VERSION ""

NS_ :

BS_:

BU_:

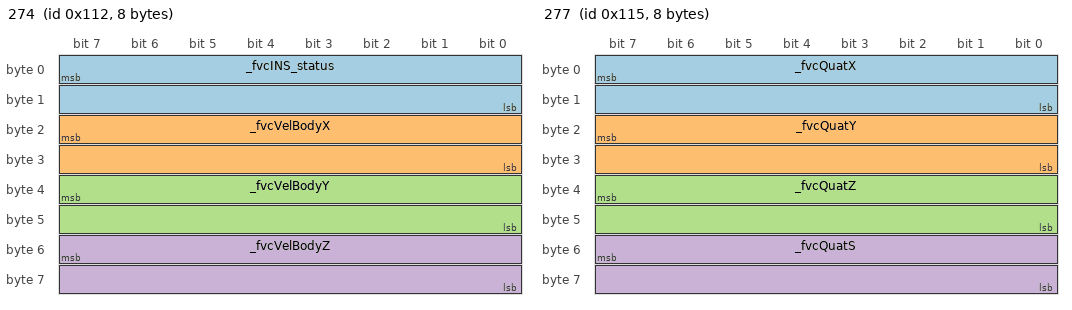
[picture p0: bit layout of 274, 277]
BO_ 274 274: 8 Vector__XXX
 SG_ _fvcINS_status : 7|16@0+ (1,0) [0|0] "unitless:" Vector__XXX
 SG_ _fvcVelBodyX : 23|16@0- (0.00427246,-70) [0|0] "unitless:" Vector__XXX
 SG_ _fvcVelBodyY : 39|16@0- (0.00427246,-70) [0|0] "unitless:" Vector__XXX
 SG_ _fvcVelBodyZ : 55|16@0- (0.00427246,-70) [0|0] "unitless:" Vector__XXX

BO_ 275 275: 8 Vector__XXX
 SG_ _fvcLatitude : 7|32@0- (0.00549324788,-90) [0|0] "angle:deg" Vector__XXX
 SG_ _fvcLongitude : 39|32@0- (0.01098633,-180) [0|0] "angle:deg" Vector__XXX

BO_ 276 276: 8 Vector__XXX
 SG_ _fvcYaw : 7|32@0- (1.67638063e-07,-180) [0|0] "angle:deg" Vector__XXX
 SG_ _fvcPitch : 39|16@0- (0.00549316406,-90) [0|0] "angle:deg" Vector__XXX
 SG_ _fvcRoll : 55|16@0- (0.01098632812,-180) [0|0] "angle:deg" Vector__XXX

BO_ 277 277: 8 Vector__XXX
 SG_ _fvcQuatX : 7|16@0- (6.103515e-05,-1) [0|0] "unitless:" Vector__XXX
 SG_ _fvcQuatY : 23|16@0- (6.103515e-05,-1) [0|0] "unitless:" Vector__XXX
 SG_ _fvcQuatZ : 39|16@0- (6.103515e-05,-1) [0|0] "unitless:" Vector__XXX
 SG_ _fvcQuatS : 55|16@0- (6.103515e-05,-1) [0|0] "unitless:" Vector__XXX

BO_ 278 278: 8 Vector__XXX
 SG_ _fvcLinBodyAccX : 7|16@0- (0.00305175781,-50) [0|0] "unitless:" Vector__XXX
 SG_ _fvcLinBodyAccY : 23|16@0- (0.00305175781,-50) [0|0] "unitless:" Vector__XXX
 SG_ _fvcLinBodyAccZ : 39|16@0- (0.00305175781,-50) [0|0] "unitless:" Vector__XXX

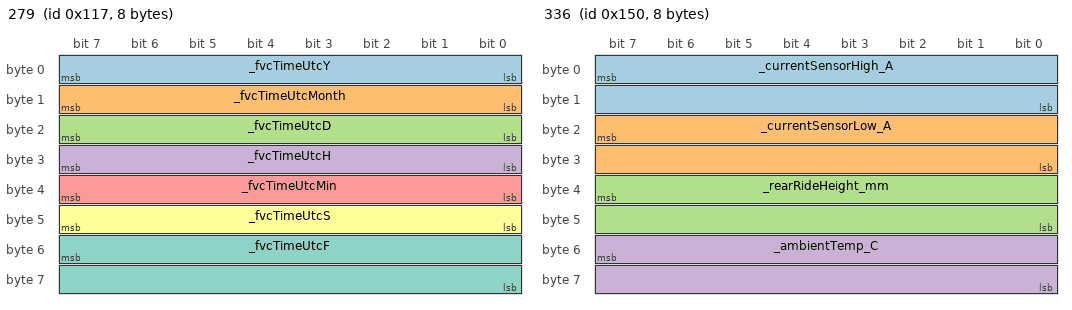
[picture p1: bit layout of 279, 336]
BO_ 279 279: 8 Vector__XXX
 SG_ _fvcTimeUtcY : 7|8@0+ (1,0) [0|0] "unitless:" Vector__XXX
 SG_ _fvcTimeUtcMonth : 15|8@0+ (1,0) [0|0] "unitless:" Vector__XXX
 SG_ _fvcTimeUtcD : 23|8@0+ (1,0) [0|0] "unitless:" Vector__XXX
 SG_ _fvcTimeUtcH : 31|8@0+ (1,0) [0|0] "unitless:" Vector__XXX
 SG_ _fvcTimeUtcMin : 39|8@0+ (1,0) [0|0] "unitless:" Vector__XXX
 SG_ _fvcTimeUtcS : 47|8@0+ (1,0) [0|0] "unitless:" Vector__XXX
 SG_ _fvcTimeUtcF : 55|16@0+ (1,0) [0|0] "unitless:" Vector__XXX

BO_ 280 280: 8 Vector__XXX
 SG_ _fvcGyroBodyX : 7|32@0- (1.862645149230957e-06,-2000) [0|0] "angular_speed:deg/s" Vector__XXX
 SG_ _fvcGyroBodyY : 39|32@0- (1.862645149230957e-06,-2000) [0|0] "angular_speed:deg/s" Vector__XXX

BO_ 281 281: 8 Vector__XXX
 SG_ _fvcGyroBodyZ : 7|32@0- (1.862645149230957e-06,-2000) [0|0] "angular_speed:deg/s" Vector__XXX
 SG_ _fvcAltitude : 47|16@0- (0.06103608758,-1000) [0|0] "unitless:" Vector__XXX

BO_ 288 288: 8 Vector__XXX
 SG_ _fvcPowerCycleNeeded : 7|8@0+ (1,0) [0|0] "unitless:" Vector__XXX

BO_ 336 336: 8 Vector__XXX
 SG_ _currentSensorHigh_A : 7|16@0- (0.1,-1000) [0|0] "voltage:V" Vector__XXX
 SG_ _currentSensorLow_A : 23|16@0- (0.01,-100) [0|0] "voltage:V" Vector__XXX
 SG_ _rearRideHeight_mm : 39|16@0- (1,0) [0|0] "distance:mm" Vector__XXX
 SG_ _ambientTemp_C : 55|16@0- (1,0) [0|0] "temperature:C" Vector__XXX

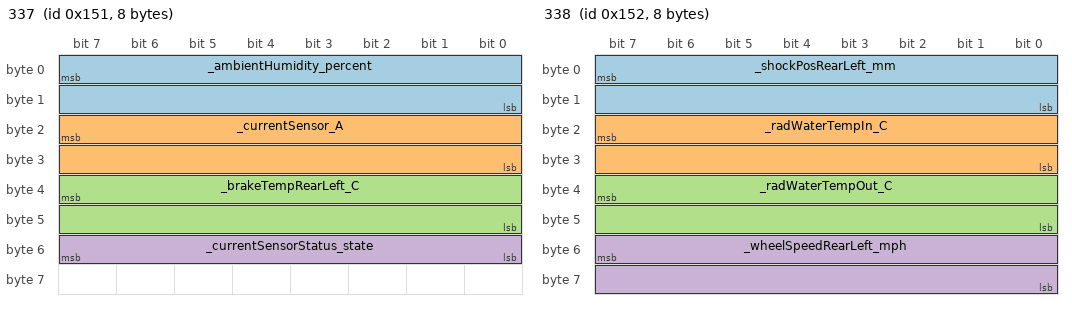
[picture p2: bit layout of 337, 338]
BO_ 337 337: 8 Vector__XXX
 SG_ _ambientHumidity_percent : 7|16@0- (0.00152590218,0) [0|0] "fraction:%" Vector__XXX
 SG_ _currentSensor_A : 23|16@0- (0.01414511329,75) [0|0] "current:A" Vector__XXX
 SG_ _brakeTempRearLeft_C : 39|16@0- (0.195360195,0) [0|0] "temperature:C" Vector__XXX
 SG_ _currentSensorStatus_state : 55|8@0+ (1,0) [0|0] "current:A" Vector__XXX

BO_ 338 338: 8 Vector__XXX
 SG_ _shockPosRearLeft_mm : 7|16@0- (0.01221001221,0) [0|0] "distance:mm" Vector__XXX
 SG_ _radWaterTempIn_C : 23|16@0- (0.0488400488,0) [0|0] "temperature:C" Vector__XXX
 SG_ _radWaterTempOut_C : 39|16@0- (0.0488400488,0) [0|0] "temperature:C" Vector__XXX
 SG_ _wheelSpeedRearLeft_mph : 55|16@0- (0.002288853283971548,0) [0|0] "speed:mph" Vector__XXX

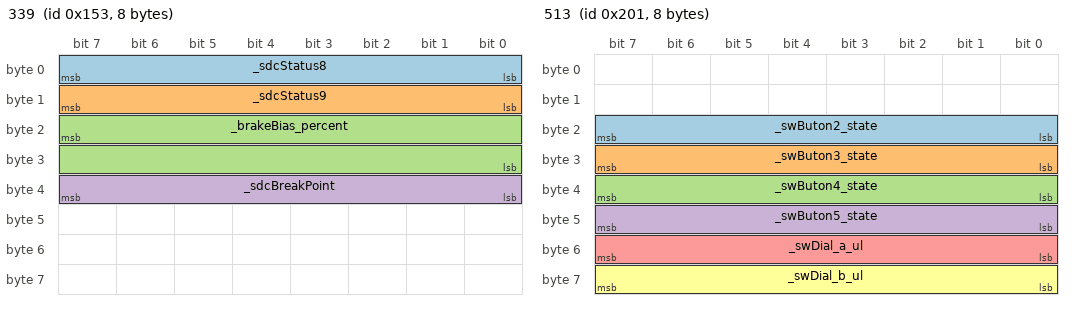
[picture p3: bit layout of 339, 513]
BO_ 339 339: 8 Vector__XXX
 SG_ _sdcStatus8 : 7|8@0+ (1,0) [0|0] "unitless:" Vector__XXX
 SG_ _sdcStatus9 : 15|8@0+ (1,0) [0|0] "unitless:" Vector__XXX
 SG_ _brakeBias_percent : 23|16@0- (1,0) [0|0] "unitless:" Vector__XXX
 SG_ _sdcBreakPoint : 39|8@0+ (1,0) [0|0] "unitless:" Vector__XXX

BO_ 340 340: 8 Vector__XXX
 SG_ _brakeTempRearRight_C : 7|16@0- (0.195360195,0) [0|0] "temperature:C" Vector__XXX
 SG_ _shockPosRearRight_mm : 23|16@0- (0.01221001221,0) [0|0] "distance:mm" Vector__XXX
 SG_ _wheelSpeedRearRight_mph : 39|16@0- (0.002288853283971548,0) [0|0] "speed:mph" Vector__XXX

BO_ 341 341: 8 Vector__XXX
 SG_ _sdcStatus5 : 7|8@0+ (1,0) [0|0] "unitless:" Vector__XXX
 SG_ _sdcStatus6 : 15|8@0+ (1,0) [0|0] "unitless:" Vector__XXX
 SG_ _sdcStatus7 : 23|8@0+ (1,0) [0|0] "unitless:" Vector__XXX

BO_ 512 512: 8 Vector__XXX
 SG_ _swButon0_state : 39|8@0+ (1,0) [0|0] "unitless:" Vector__XXX
 SG_ _swButon1_state : 47|8@0+ (1,0) [0|0] "unitless:" Vector__XXX
 SG_ _displayPage_state : 55|8@0+ (1,0) [0|0] "unitless:" Vector__XXX

BO_ 513 513: 8 Vector__XXX
 SG_ _swButon2_state : 23|8@0+ (1,0) [0|0] "unitless:" Vector__XXX
 SG_ _swButon3_state : 31|8@0+ (1,0) [0|0] "unitless:" Vector__XXX
 SG_ _swButon4_state : 39|8@0+ (1,0) [0|0] "unitless:" Vector__XXX
 SG_ _swButon5_state : 47|8@0+ (1,0) [0|0] "unitless:" Vector__XXX
 SG_ _swDial_a_ul : 55|8@0+ (1,0) [0|0] "unitless:" Vector__XXX
 SG_ _swDial_b_ul : 63|8@0+ (1,0) [0|0] "unitless:" Vector__XXX

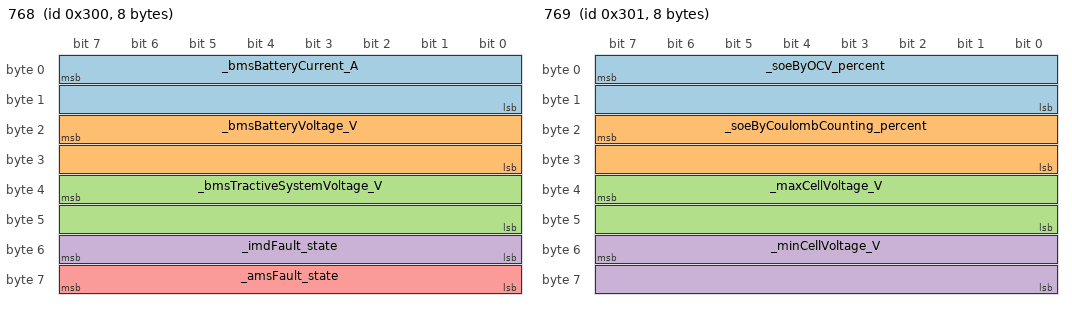
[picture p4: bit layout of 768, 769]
BO_ 768 768: 8 Vector__XXX
 SG_ _bmsBatteryCurrent_A : 7|16@0- (0.01,-300) [0|0] "current:A" Vector__XXX
 SG_ _bmsBatteryVoltage_V : 23|16@0- (0.1,0) [0|0] "voltage:V" Vector__XXX
 SG_ _bmsTractiveSystemVoltage_V : 39|16@0- (0.1,0) [0|0] "voltage:V" Vector__XXX
 SG_ _imdFault_state : 55|8@0+ (1,0) [0|0] "unitless:" Vector__XXX
 SG_ _amsFault_state : 63|8@0+ (1,0) [0|0] "unitless:" Vector__XXX

BO_ 769 769: 8 Vector__XXX
 SG_ _soeByOCV_percent : 7|16@0- (0.01,0) [0|0] "fraction:%" Vector__XXX
 SG_ _soeByCoulombCounting_percent : 23|16@0- (0.01,0) [0|0] "fraction:%" Vector__XXX
 SG_ _maxCellVoltage_V : 39|16@0- (0.01,0) [0|0] "voltage:V" Vector__XXX
 SG_ _minCellVoltage_V : 55|16@0- (0.01,0) [0|0] "voltage:V" Vector__XXX

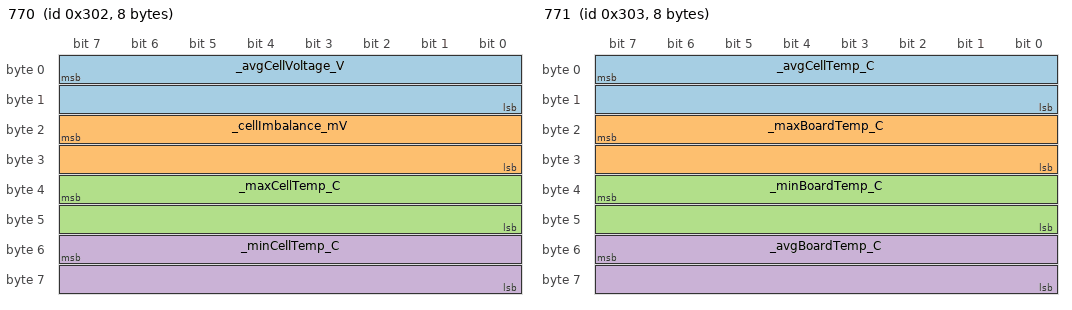
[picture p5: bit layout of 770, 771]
BO_ 770 770: 8 Vector__XXX
 SG_ _avgCellVoltage_V : 7|16@0- (0.01,0) [0|0] "voltage:V" Vector__XXX
 SG_ _cellImbalance_mV : 23|16@0- (0.1,0) [0|0] "voltage:mV" Vector__XXX
 SG_ _maxCellTemp_C : 39|16@0- (0.1,-40) [0|0] "temperature:C" Vector__XXX
 SG_ _minCellTemp_C : 55|16@0- (0.1,-40) [0|0] "temperature:C" Vector__XXX

BO_ 771 771: 8 Vector__XXX
 SG_ _avgCellTemp_C : 7|16@0- (0.1,-40) [0|0] "temperature:C" Vector__XXX
 SG_ _maxBoardTemp_C : 23|16@0- (0.1,-40) [0|0] "temperature:C" Vector__XXX
 SG_ _minBoardTemp_C : 39|16@0- (0.1,-40) [0|0] "temperature:C" Vector__XXX
 SG_ _avgBoardTemp_C : 55|16@0- (0.1,-40) [0|0] "temperature:C" Vector__XXX

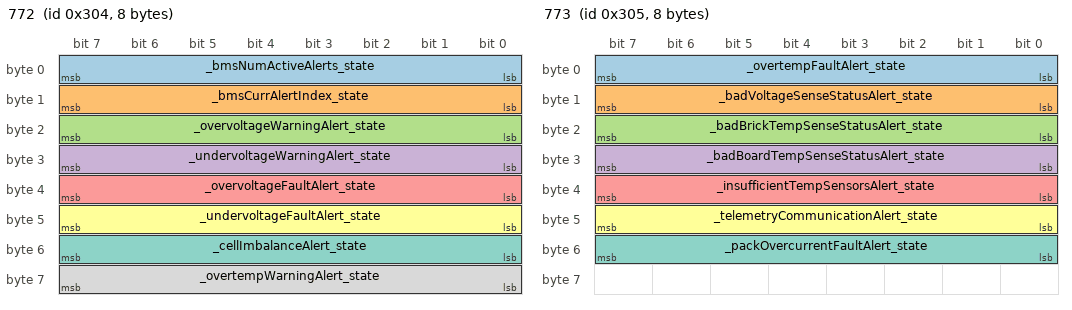
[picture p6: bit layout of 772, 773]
BO_ 772 772: 8 Vector__XXX
 SG_ _bmsNumActiveAlerts_state : 7|8@0+ (1,0) [0|0] "unitless:" Vector__XXX
 SG_ _bmsCurrAlertIndex_state : 15|8@0+ (1,0) [0|0] "unitless:" Vector__XXX
 SG_ _overvoltageWarningAlert_state : 23|8@0+ (1,0) [0|0] "unitless:" Vector__XXX
 SG_ _undervoltageWarningAlert_state : 31|8@0+ (1,0) [0|0] "unitless:" Vector__XXX
 SG_ _overvoltageFaultAlert_state : 39|8@0+ (1,0) [0|0] "unitless:" Vector__XXX
 SG_ _undervoltageFaultAlert_state : 47|8@0+ (1,0) [0|0] "unitless:" Vector__XXX
 SG_ _cellImbalanceAlert_state : 55|8@0+ (1,0) [0|0] "unitless:" Vector__XXX
 SG_ _overtempWarningAlert_state : 63|8@0+ (1,0) [0|0] "unitless:" Vector__XXX

BO_ 773 773: 8 Vector__XXX
 SG_ _overtempFaultAlert_state : 7|8@0+ (1,0) [0|0] "unitless:" Vector__XXX
 SG_ _badVoltageSenseStatusAlert_state : 15|8@0+ (1,0) [0|0] "unitless:" Vector__XXX
 SG_ _badBrickTempSenseStatusAlert_state : 23|8@0+ (1,0) [0|0] "unitless:" Vector__XXX
 SG_ _badBoardTempSenseStatusAlert_state : 31|8@0+ (1,0) [0|0] "unitless:" Vector__XXX
 SG_ _insufficientTempSensorsAlert_state : 39|8@0+ (1,0) [0|0] "unitless:" Vector__XXX
 SG_ _telemetryCommunicationAlert_state : 47|8@0+ (1,0) [0|0] "unitless:" Vector__XXX
 SG_ _packOvercurrentFaultAlert_state : 55|8@0+ (1,0) [0|0] "unitless:" Vector__XXX

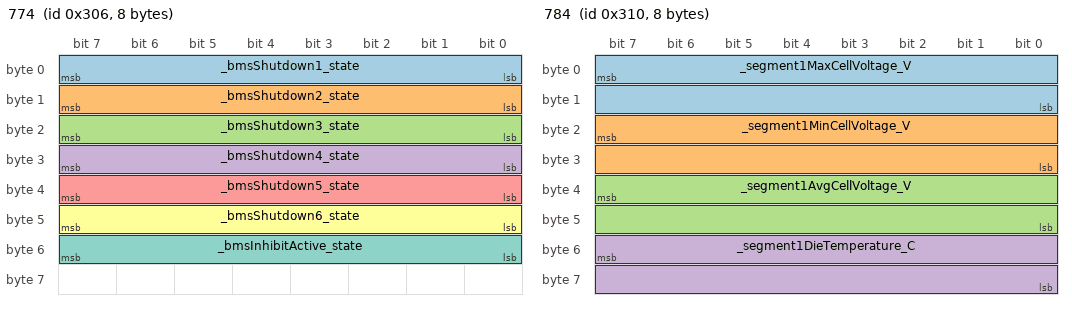
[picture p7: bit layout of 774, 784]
BO_ 774 774: 8 Vector__XXX
 SG_ _bmsShutdown1_state : 7|8@0+ (1,0) [0|0] "unitless:" Vector__XXX
 SG_ _bmsShutdown2_state : 15|8@0+ (1,0) [0|0] "unitless:" Vector__XXX
 SG_ _bmsShutdown3_state : 23|8@0+ (1,0) [0|0] "unitless:" Vector__XXX
 SG_ _bmsShutdown4_state : 31|8@0+ (1,0) [0|0] "unitless:" Vector__XXX
 SG_ _bmsShutdown5_state : 39|8@0+ (1,0) [0|0] "unitless:" Vector__XXX
 SG_ _bmsShutdown6_state : 47|8@0+ (1,0) [0|0] "unitless:" Vector__XXX
 SG_ _bmsInhibitActive_state : 55|8@0+ (1,0) [0|0] "unitless:" Vector__XXX

BO_ 784 784: 8 Vector__XXX
 SG_ _segment1MaxCellVoltage_V : 7|16@0- (0.001,0) [0|0] "voltage:V" Vector__XXX
 SG_ _segment1MinCellVoltage_V : 23|16@0- (0.001,0) [0|0] "voltage:V" Vector__XXX
 SG_ _segment1AvgCellVoltage_V : 39|16@0- (0.001,0) [0|0] "voltage:V" Vector__XXX
 SG_ _segment1DieTemperature_C : 55|16@0- (0.1,-40) [0|0] "temperature:C" Vector__XXX

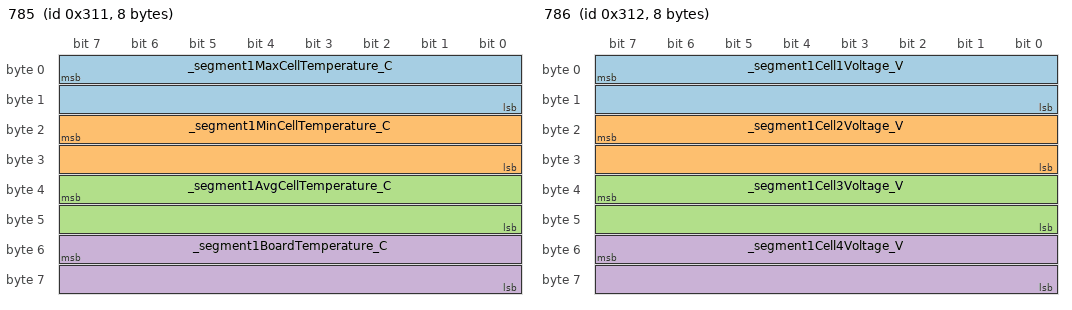
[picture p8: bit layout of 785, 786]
BO_ 785 785: 8 Vector__XXX
 SG_ _segment1MaxCellTemperature_C : 7|16@0- (0.1,-40) [0|0] "temperature:C" Vector__XXX
 SG_ _segment1MinCellTemperature_C : 23|16@0- (0.1,-40) [0|0] "temperature:C" Vector__XXX
 SG_ _segment1AvgCellTemperature_C : 39|16@0- (0.1,-40) [0|0] "temperature:C" Vector__XXX
 SG_ _segment1BoardTemperature_C : 55|16@0- (0.1,-40) [0|0] "temperature:C" Vector__XXX

BO_ 786 786: 8 Vector__XXX
 SG_ _segment1Cell1Voltage_V : 7|16@0- (0.001,0) [0|0] "voltage:V" Vector__XXX
 SG_ _segment1Cell2Voltage_V : 23|16@0- (0.001,0) [0|0] "voltage:V" Vector__XXX
 SG_ _segment1Cell3Voltage_V : 39|16@0- (0.001,0) [0|0] "voltage:V" Vector__XXX
 SG_ _segment1Cell4Voltage_V : 55|16@0- (0.001,0) [0|0] "voltage:V" Vector__XXX

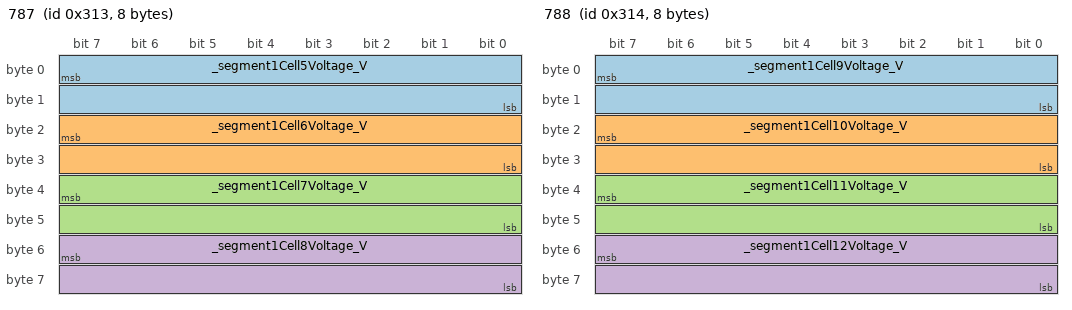
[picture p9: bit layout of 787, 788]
BO_ 787 787: 8 Vector__XXX
 SG_ _segment1Cell5Voltage_V : 7|16@0- (0.001,0) [0|0] "voltage:V" Vector__XXX
 SG_ _segment1Cell6Voltage_V : 23|16@0- (0.001,0) [0|0] "voltage:V" Vector__XXX
 SG_ _segment1Cell7Voltage_V : 39|16@0- (0.001,0) [0|0] "voltage:V" Vector__XXX
 SG_ _segment1Cell8Voltage_V : 55|16@0- (0.001,0) [0|0] "voltage:V" Vector__XXX

BO_ 788 788: 8 Vector__XXX
 SG_ _segment1Cell9Voltage_V : 7|16@0- (0.001,0) [0|0] "voltage:V" Vector__XXX
 SG_ _segment1Cell10Voltage_V : 23|16@0- (0.001,0) [0|0] "voltage:V" Vector__XXX
 SG_ _segment1Cell11Voltage_V : 39|16@0- (0.001,0) [0|0] "voltage:V" Vector__XXX
 SG_ _segment1Cell12Voltage_V : 55|16@0- (0.001,0) [0|0] "voltage:V" Vector__XXX

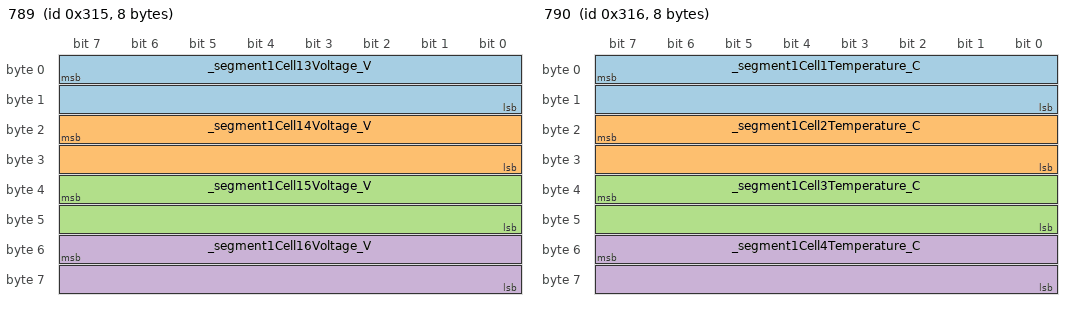
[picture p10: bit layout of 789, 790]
BO_ 789 789: 8 Vector__XXX
 SG_ _segment1Cell13Voltage_V : 7|16@0- (0.001,0) [0|0] "voltage:V" Vector__XXX
 SG_ _segment1Cell14Voltage_V : 23|16@0- (0.001,0) [0|0] "voltage:V" Vector__XXX
 SG_ _segment1Cell15Voltage_V : 39|16@0- (0.001,0) [0|0] "voltage:V" Vector__XXX
 SG_ _segment1Cell16Voltage_V : 55|16@0- (0.001,0) [0|0] "voltage:V" Vector__XXX

BO_ 790 790: 8 Vector__XXX
 SG_ _segment1Cell1Temperature_C : 7|16@0- (0.1,-40) [0|0] "temperature:C" Vector__XXX
 SG_ _segment1Cell2Temperature_C : 23|16@0- (0.1,-40) [0|0] "temperature:C" Vector__XXX
 SG_ _segment1Cell3Temperature_C : 39|16@0- (0.1,-40) [0|0] "temperature:C" Vector__XXX
 SG_ _segment1Cell4Temperature_C : 55|16@0- (0.1,-40) [0|0] "temperature:C" Vector__XXX

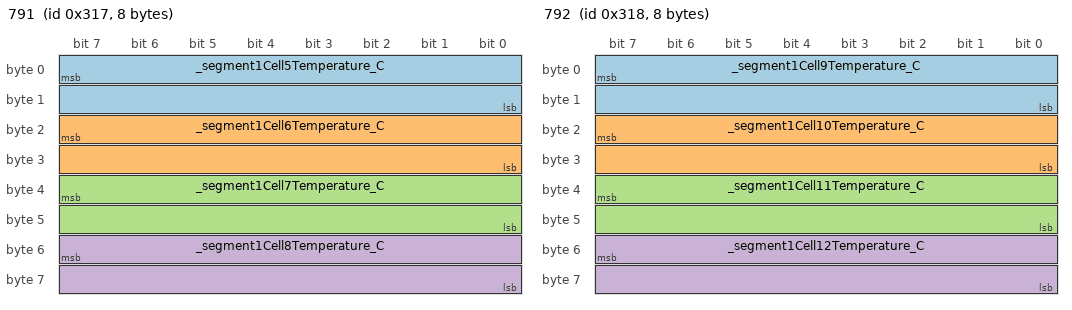
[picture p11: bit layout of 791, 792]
BO_ 791 791: 8 Vector__XXX
 SG_ _segment1Cell5Temperature_C : 7|16@0- (0.1,-40) [0|0] "temperature:C" Vector__XXX
 SG_ _segment1Cell6Temperature_C : 23|16@0- (0.1,-40) [0|0] "temperature:C" Vector__XXX
 SG_ _segment1Cell7Temperature_C : 39|16@0- (0.1,-40) [0|0] "temperature:C" Vector__XXX
 SG_ _segment1Cell8Temperature_C : 55|16@0- (0.1,-40) [0|0] "temperature:C" Vector__XXX

BO_ 792 792: 8 Vector__XXX
 SG_ _segment1Cell9Temperature_C : 7|16@0- (0.1,-40) [0|0] "temperature:C" Vector__XXX
 SG_ _segment1Cell10Temperature_C : 23|16@0- (0.1,-40) [0|0] "temperature:C" Vector__XXX
 SG_ _segment1Cell11Temperature_C : 39|16@0- (0.1,-40) [0|0] "temperature:C" Vector__XXX
 SG_ _segment1Cell12Temperature_C : 55|16@0- (0.1,-40) [0|0] "temperature:C" Vector__XXX

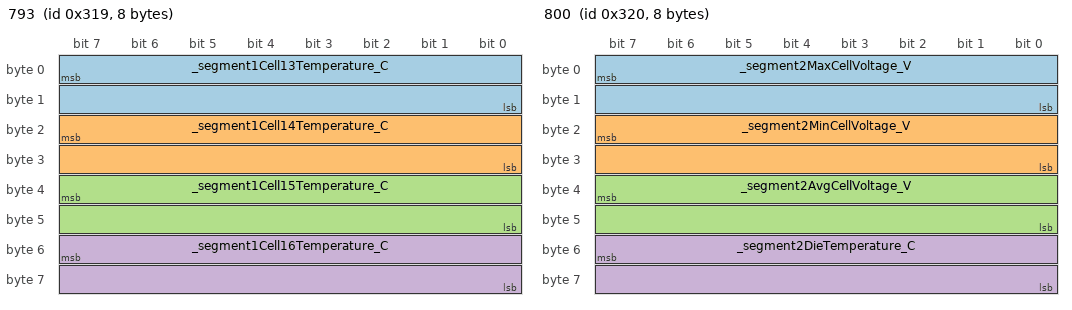
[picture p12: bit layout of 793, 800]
BO_ 793 793: 8 Vector__XXX
 SG_ _segment1Cell13Temperature_C : 7|16@0- (0.1,-40) [0|0] "temperature:C" Vector__XXX
 SG_ _segment1Cell14Temperature_C : 23|16@0- (0.1,-40) [0|0] "temperature:C" Vector__XXX
 SG_ _segment1Cell15Temperature_C : 39|16@0- (0.1,-40) [0|0] "temperature:C" Vector__XXX
 SG_ _segment1Cell16Temperature_C : 55|16@0- (0.1,-40) [0|0] "temperature:C" Vector__XXX

BO_ 800 800: 8 Vector__XXX
 SG_ _segment2MaxCellVoltage_V : 7|16@0- (0.001,0) [0|0] "voltage:V" Vector__XXX
 SG_ _segment2MinCellVoltage_V : 23|16@0- (0.001,0) [0|0] "voltage:V" Vector__XXX
 SG_ _segment2AvgCellVoltage_V : 39|16@0- (0.001,0) [0|0] "voltage:V" Vector__XXX
 SG_ _segment2DieTemperature_C : 55|16@0- (0.1,-40) [0|0] "temperature:C" Vector__XXX

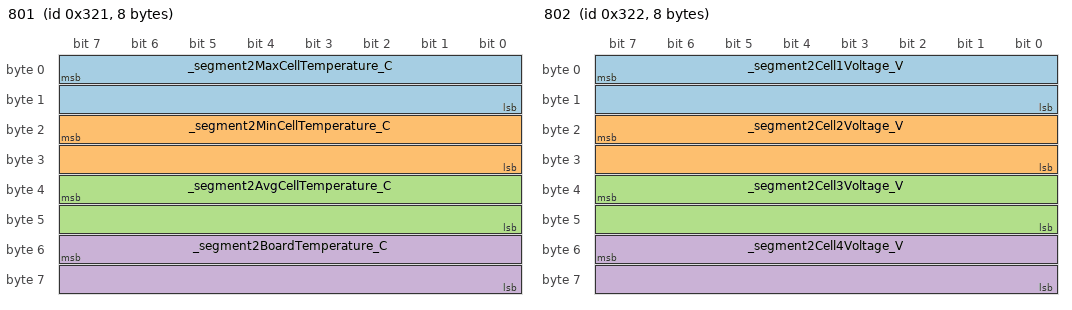
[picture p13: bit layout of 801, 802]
BO_ 801 801: 8 Vector__XXX
 SG_ _segment2MaxCellTemperature_C : 7|16@0- (0.1,-40) [0|0] "temperature:C" Vector__XXX
 SG_ _segment2MinCellTemperature_C : 23|16@0- (0.1,-40) [0|0] "temperature:C" Vector__XXX
 SG_ _segment2AvgCellTemperature_C : 39|16@0- (0.1,-40) [0|0] "temperature:C" Vector__XXX
 SG_ _segment2BoardTemperature_C : 55|16@0- (0.1,-40) [0|0] "temperature:C" Vector__XXX

BO_ 802 802: 8 Vector__XXX
 SG_ _segment2Cell1Voltage_V : 7|16@0- (0.001,0) [0|0] "voltage:V" Vector__XXX
 SG_ _segment2Cell2Voltage_V : 23|16@0- (0.001,0) [0|0] "voltage:V" Vector__XXX
 SG_ _segment2Cell3Voltage_V : 39|16@0- (0.001,0) [0|0] "voltage:V" Vector__XXX
 SG_ _segment2Cell4Voltage_V : 55|16@0- (0.001,0) [0|0] "voltage:V" Vector__XXX

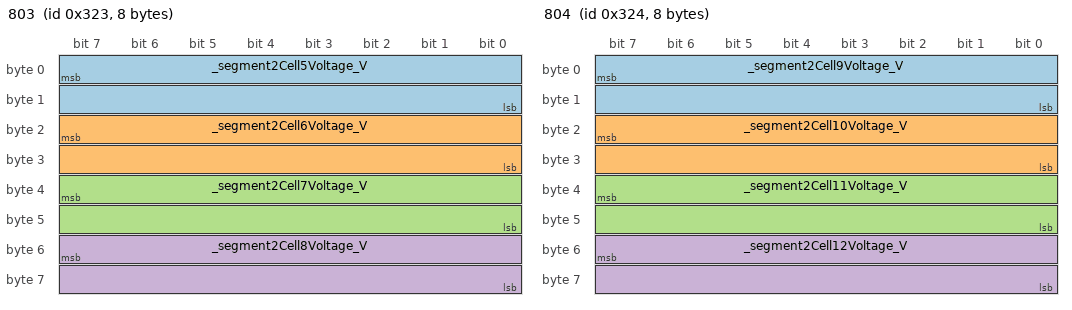
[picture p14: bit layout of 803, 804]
BO_ 803 803: 8 Vector__XXX
 SG_ _segment2Cell5Voltage_V : 7|16@0- (0.001,0) [0|0] "voltage:V" Vector__XXX
 SG_ _segment2Cell6Voltage_V : 23|16@0- (0.001,0) [0|0] "voltage:V" Vector__XXX
 SG_ _segment2Cell7Voltage_V : 39|16@0- (0.001,0) [0|0] "voltage:V" Vector__XXX
 SG_ _segment2Cell8Voltage_V : 55|16@0- (0.001,0) [0|0] "voltage:V" Vector__XXX

BO_ 804 804: 8 Vector__XXX
 SG_ _segment2Cell9Voltage_V : 7|16@0- (0.001,0) [0|0] "voltage:V" Vector__XXX
 SG_ _segment2Cell10Voltage_V : 23|16@0- (0.001,0) [0|0] "voltage:V" Vector__XXX
 SG_ _segment2Cell11Voltage_V : 39|16@0- (0.001,0) [0|0] "voltage:V" Vector__XXX
 SG_ _segment2Cell12Voltage_V : 55|16@0- (0.001,0) [0|0] "voltage:V" Vector__XXX

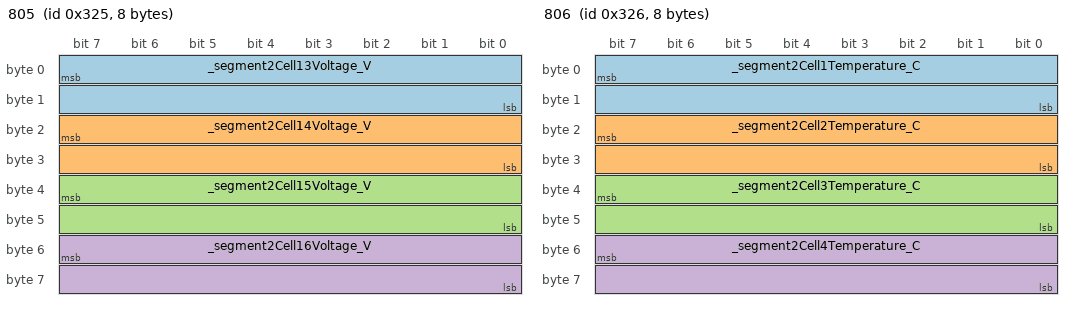
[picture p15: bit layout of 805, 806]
BO_ 805 805: 8 Vector__XXX
 SG_ _segment2Cell13Voltage_V : 7|16@0- (0.001,0) [0|0] "voltage:V" Vector__XXX
 SG_ _segment2Cell14Voltage_V : 23|16@0- (0.001,0) [0|0] "voltage:V" Vector__XXX
 SG_ _segment2Cell15Voltage_V : 39|16@0- (0.001,0) [0|0] "voltage:V" Vector__XXX
 SG_ _segment2Cell16Voltage_V : 55|16@0- (0.001,0) [0|0] "voltage:V" Vector__XXX

BO_ 806 806: 8 Vector__XXX
 SG_ _segment2Cell1Temperature_C : 7|16@0- (0.1,-40) [0|0] "temperature:C" Vector__XXX
 SG_ _segment2Cell2Temperature_C : 23|16@0- (0.1,-40) [0|0] "temperature:C" Vector__XXX
 SG_ _segment2Cell3Temperature_C : 39|16@0- (0.1,-40) [0|0] "temperature:C" Vector__XXX
 SG_ _segment2Cell4Temperature_C : 55|16@0- (0.1,-40) [0|0] "temperature:C" Vector__XXX

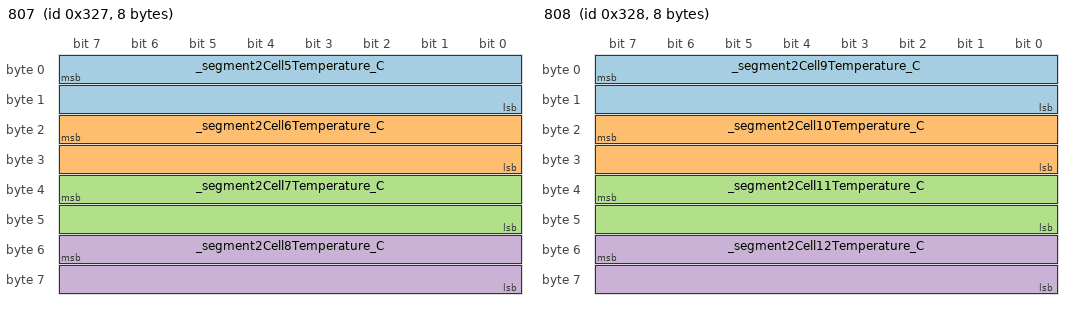
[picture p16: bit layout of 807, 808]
BO_ 807 807: 8 Vector__XXX
 SG_ _segment2Cell5Temperature_C : 7|16@0- (0.1,-40) [0|0] "temperature:C" Vector__XXX
 SG_ _segment2Cell6Temperature_C : 23|16@0- (0.1,-40) [0|0] "temperature:C" Vector__XXX
 SG_ _segment2Cell7Temperature_C : 39|16@0- (0.1,-40) [0|0] "temperature:C" Vector__XXX
 SG_ _segment2Cell8Temperature_C : 55|16@0- (0.1,-40) [0|0] "temperature:C" Vector__XXX

BO_ 808 808: 8 Vector__XXX
 SG_ _segment2Cell9Temperature_C : 7|16@0- (0.1,-40) [0|0] "temperature:C" Vector__XXX
 SG_ _segment2Cell10Temperature_C : 23|16@0- (0.1,-40) [0|0] "temperature:C" Vector__XXX
 SG_ _segment2Cell11Temperature_C : 39|16@0- (0.1,-40) [0|0] "temperature:C" Vector__XXX
 SG_ _segment2Cell12Temperature_C : 55|16@0- (0.1,-40) [0|0] "temperature:C" Vector__XXX

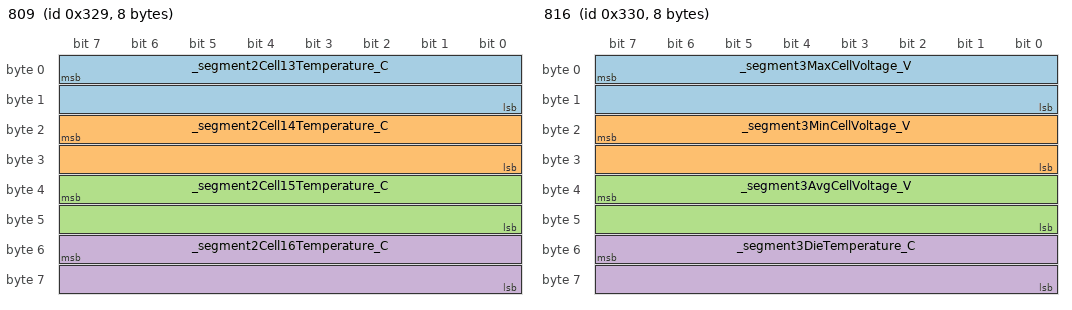
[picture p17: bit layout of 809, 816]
BO_ 809 809: 8 Vector__XXX
 SG_ _segment2Cell13Temperature_C : 7|16@0- (0.1,-40) [0|0] "temperature:C" Vector__XXX
 SG_ _segment2Cell14Temperature_C : 23|16@0- (0.1,-40) [0|0] "temperature:C" Vector__XXX
 SG_ _segment2Cell15Temperature_C : 39|16@0- (0.1,-40) [0|0] "temperature:C" Vector__XXX
 SG_ _segment2Cell16Temperature_C : 55|16@0- (0.1,-40) [0|0] "temperature:C" Vector__XXX

BO_ 816 816: 8 Vector__XXX
 SG_ _segment3MaxCellVoltage_V : 7|16@0- (0.001,0) [0|0] "voltage:V" Vector__XXX
 SG_ _segment3MinCellVoltage_V : 23|16@0- (0.001,0) [0|0] "voltage:V" Vector__XXX
 SG_ _segment3AvgCellVoltage_V : 39|16@0- (0.001,0) [0|0] "voltage:V" Vector__XXX
 SG_ _segment3DieTemperature_C : 55|16@0- (0.1,-40) [0|0] "temperature:C" Vector__XXX

BO_ 817 817: 8 Vector__XXX
 SG_ _segment3MaxCellTemperature_C : 7|16@0- (0.1,-40) [0|0] "temperature:C" Vector__XXX
 SG_ _segment3MinCellTemperature_C : 23|16@0- (0.1,-40) [0|0] "temperature:C" Vector__XXX
 SG_ _segment3AvgCellTemperature_C : 39|16@0- (0.1,-40) [0|0] "temperature:C" Vector__XXX
 SG_ _segment3BoardTemperature_C : 55|16@0- (0.1,-40) [0|0] "temperature:C" Vector__XXX

BO_ 818 818: 8 Vector__XXX
 SG_ _segment3Cell1Voltage_V : 7|16@0- (0.001,0) [0|0] "voltage:V" Vector__XXX
 SG_ _segment3Cell2Voltage_V : 23|16@0- (0.001,0) [0|0] "voltage:V" Vector__XXX
 SG_ _segment3Cell3Voltage_V : 39|16@0- (0.001,0) [0|0] "voltage:V" Vector__XXX
 SG_ _segment3Cell4Voltage_V : 55|16@0- (0.001,0) [0|0] "voltage:V" Vector__XXX

BO_ 819 819: 8 Vector__XXX
 SG_ _segment3Cell5Voltage_V : 7|16@0- (0.001,0) [0|0] "voltage:V" Vector__XXX
 SG_ _segment3Cell6Voltage_V : 23|16@0- (0.001,0) [0|0] "voltage:V" Vector__XXX
 SG_ _segment3Cell7Voltage_V : 39|16@0- (0.001,0) [0|0] "voltage:V" Vector__XXX
 SG_ _segment3Cell8Voltage_V : 55|16@0- (0.001,0) [0|0] "voltage:V" Vector__XXX

BO_ 820 820: 8 Vector__XXX
 SG_ _segment3Cell9Voltage_V : 7|16@0- (0.001,0) [0|0] "voltage:V" Vector__XXX
 SG_ _segment3Cell10Voltage_V : 23|16@0- (0.001,0) [0|0] "voltage:V" Vector__XXX
 SG_ _segment3Cell11Voltage_V : 39|16@0- (0.001,0) [0|0] "voltage:V" Vector__XXX
 SG_ _segment3Cell12Voltage_V : 55|16@0- (0.001,0) [0|0] "voltage:V" Vector__XXX

BO_ 821 821: 8 Vector__XXX
 SG_ _segment3Cell13Voltage_V : 7|16@0- (0.001,0) [0|0] "voltage:V" Vector__XXX
 SG_ _segment3Cell14Voltage_V : 23|16@0- (0.001,0) [0|0] "voltage:V" Vector__XXX
 SG_ _segment3Cell15Voltage_V : 39|16@0- (0.001,0) [0|0] "voltage:V" Vector__XXX
 SG_ _segment3Cell16Voltage_V : 55|16@0- (0.001,0) [0|0] "voltage:V" Vector__XXX

BO_ 822 822: 8 Vector__XXX
 SG_ _segment3Cell1Temperature_C : 7|16@0- (0.1,-40) [0|0] "temperature:C" Vector__XXX
 SG_ _segment3Cell2Temperature_C : 23|16@0- (0.1,-40) [0|0] "temperature:C" Vector__XXX
 SG_ _segment3Cell3Temperature_C : 39|16@0- (0.1,-40) [0|0] "temperature:C" Vector__XXX
 SG_ _segment3Cell4Temperature_C : 55|16@0- (0.1,-40) [0|0] "temperature:C" Vector__XXX

BO_ 823 823: 8 Vector__XXX
 SG_ _segment3Cell5Temperature_C : 7|16@0- (0.1,-40) [0|0] "temperature:C" Vector__XXX
 SG_ _segment3Cell6Temperature_C : 23|16@0- (0.1,-40) [0|0] "temperature:C" Vector__XXX
 SG_ _segment3Cell7Temperature_C : 39|16@0- (0.1,-40) [0|0] "temperature:C" Vector__XXX
 SG_ _segment3Cell8Temperature_C : 55|16@0- (0.1,-40) [0|0] "temperature:C" Vector__XXX

BO_ 824 824: 8 Vector__XXX
 SG_ _segment3Cell9Temperature_C : 7|16@0- (0.1,-40) [0|0] "temperature:C" Vector__XXX
 SG_ _segment3Cell10Temperature_C : 23|16@0- (0.1,-40) [0|0] "temperature:C" Vector__XXX
 SG_ _segment3Cell11Temperature_C : 39|16@0- (0.1,-40) [0|0] "temperature:C" Vector__XXX
 SG_ _segment3Cell12Temperature_C : 55|16@0- (0.1,-40) [0|0] "temperature:C" Vector__XXX

BO_ 825 825: 8 Vector__XXX
 SG_ _segment3Cell13Temperature_C : 7|16@0- (0.1,-40) [0|0] "temperature:C" Vector__XXX
 SG_ _segment3Cell14Temperature_C : 23|16@0- (0.1,-40) [0|0] "temperature:C" Vector__XXX
 SG_ _segment3Cell15Temperature_C : 39|16@0- (0.1,-40) [0|0] "temperature:C" Vector__XXX
 SG_ _segment3Cell16Temperature_C : 55|16@0- (0.1,-40) [0|0] "temperature:C" Vector__XXX

BO_ 832 832: 8 Vector__XXX
 SG_ _segment4MaxCellVoltage_V : 7|16@0- (0.001,0) [0|0] "voltage:V" Vector__XXX
 SG_ _segment4MinCellVoltage_V : 23|16@0- (0.001,0) [0|0] "voltage:V" Vector__XXX
 SG_ _segment4AvgCellVoltage_V : 39|16@0- (0.001,0) [0|0] "voltage:V" Vector__XXX
 SG_ _segment4DieTemperature_C : 55|16@0- (0.1,-40) [0|0] "temperature:C" Vector__XXX

BO_ 833 833: 8 Vector__XXX
 SG_ _segment4MaxCellTemperature_C : 7|16@0- (0.1,-40) [0|0] "temperature:C" Vector__XXX
 SG_ _segment4MinCellTemperature_C : 23|16@0- (0.1,-40) [0|0] "temperature:C" Vector__XXX
 SG_ _segment4AvgCellTemperature_C : 39|16@0- (0.1,-40) [0|0] "temperature:C" Vector__XXX
 SG_ _segment4BoardTemperature_C : 55|16@0- (0.1,-40) [0|0] "temperature:C" Vector__XXX

BO_ 834 834: 8 Vector__XXX
 SG_ _segment4Cell1Voltage_V : 7|16@0- (0.001,0) [0|0] "voltage:V" Vector__XXX
 SG_ _segment4Cell2Voltage_V : 23|16@0- (0.001,0) [0|0] "voltage:V" Vector__XXX
 SG_ _segment4Cell3Voltage_V : 39|16@0- (0.001,0) [0|0] "voltage:V" Vector__XXX
 SG_ _segment4Cell4Voltage_V : 55|16@0- (0.001,0) [0|0] "voltage:V" Vector__XXX

BO_ 835 835: 8 Vector__XXX
 SG_ _segment4Cell5Voltage_V : 7|16@0- (0.001,0) [0|0] "voltage:V" Vector__XXX
 SG_ _segment4Cell6Voltage_V : 23|16@0- (0.001,0) [0|0] "voltage:V" Vector__XXX
 SG_ _segment4Cell7Voltage_V : 39|16@0- (0.001,0) [0|0] "voltage:V" Vector__XXX
 SG_ _segment4Cell8Voltage_V : 55|16@0- (0.001,0) [0|0] "voltage:V" Vector__XXX

BO_ 836 836: 8 Vector__XXX
 SG_ _segment4Cell9Voltage_V : 7|16@0- (0.001,0) [0|0] "voltage:V" Vector__XXX
 SG_ _segment4Cell10Voltage_V : 23|16@0- (0.001,0) [0|0] "voltage:V" Vector__XXX
 SG_ _segment4Cell11Voltage_V : 39|16@0- (0.001,0) [0|0] "voltage:V" Vector__XXX
 SG_ _segment4Cell12Voltage_V : 55|16@0- (0.001,0) [0|0] "voltage:V" Vector__XXX

BO_ 837 837: 8 Vector__XXX
 SG_ _segment4Cell13Voltage_V : 7|16@0- (0.001,0) [0|0] "voltage:V" Vector__XXX
 SG_ _segment4Cell14Voltage_V : 23|16@0- (0.001,0) [0|0] "voltage:V" Vector__XXX
 SG_ _segment4Cell15Voltage_V : 39|16@0- (0.001,0) [0|0] "voltage:V" Vector__XXX
 SG_ _segment4Cell16Voltage_V : 55|16@0- (0.001,0) [0|0] "voltage:V" Vector__XXX

BO_ 838 838: 8 Vector__XXX
 SG_ _segment4Cell1Temperature_C : 7|16@0- (0.1,-40) [0|0] "temperature:C" Vector__XXX
 SG_ _segment4Cell2Temperature_C : 23|16@0- (0.1,-40) [0|0] "temperature:C" Vector__XXX
 SG_ _segment4Cell3Temperature_C : 39|16@0- (0.1,-40) [0|0] "temperature:C" Vector__XXX
 SG_ _segment4Cell4Temperature_C : 55|16@0- (0.1,-40) [0|0] "temperature:C" Vector__XXX

BO_ 839 839: 8 Vector__XXX
 SG_ _segment4Cell5Temperature_C : 7|16@0- (0.1,-40) [0|0] "temperature:C" Vector__XXX
 SG_ _segment4Cell6Temperature_C : 23|16@0- (0.1,-40) [0|0] "temperature:C" Vector__XXX
 SG_ _segment4Cell7Temperature_C : 39|16@0- (0.1,-40) [0|0] "temperature:C" Vector__XXX
 SG_ _segment4Cell8Temperature_C : 55|16@0- (0.1,-40) [0|0] "temperature:C" Vector__XXX

BO_ 840 840: 8 Vector__XXX
 SG_ _segment4Cell9Temperature_C : 7|16@0- (0.1,-40) [0|0] "temperature:C" Vector__XXX
 SG_ _segment4Cell10Temperature_C : 23|16@0- (0.1,-40) [0|0] "temperature:C" Vector__XXX
 SG_ _segment4Cell11Temperature_C : 39|16@0- (0.1,-40) [0|0] "temperature:C" Vector__XXX
 SG_ _segment4Cell12Temperature_C : 55|16@0- (0.1,-40) [0|0] "temperature:C" Vector__XXX

BO_ 841 841: 8 Vector__XXX
 SG_ _segment4Cell13Temperature_C : 7|16@0- (0.1,-40) [0|0] "temperature:C" Vector__XXX
 SG_ _segment4Cell14Temperature_C : 23|16@0- (0.1,-40) [0|0] "temperature:C" Vector__XXX
 SG_ _segment4Cell15Temperature_C : 39|16@0- (0.1,-40) [0|0] "temperature:C" Vector__XXX
 SG_ _segment4Cell16Temperature_C : 55|16@0- (0.1,-40) [0|0] "temperature:C" Vector__XXX

BO_ 848 848: 8 Vector__XXX
 SG_ _segment5MaxCellVoltage_V : 7|16@0- (0.001,0) [0|0] "voltage:V" Vector__XXX
 SG_ _segment5MinCellVoltage_V : 23|16@0- (0.001,0) [0|0] "voltage:V" Vector__XXX
 SG_ _segment5AvgCellVoltage_V : 39|16@0- (0.001,0) [0|0] "voltage:V" Vector__XXX
 SG_ _segment5DieTemperature_C : 55|16@0- (0.1,-40) [0|0] "temperature:C" Vector__XXX

BO_ 849 849: 8 Vector__XXX
 SG_ _segment5MaxCellTemperature_C : 7|16@0- (0.1,-40) [0|0] "temperature:C" Vector__XXX
 SG_ _segment5MinCellTemperature_C : 23|16@0- (0.1,-40) [0|0] "temperature:C" Vector__XXX
 SG_ _segment5AvgCellTemperature_C : 39|16@0- (0.1,-40) [0|0] "temperature:C" Vector__XXX
 SG_ _segment5BoardTemperature_C : 55|16@0- (0.1,-40) [0|0] "temperature:C" Vector__XXX

BO_ 850 850: 8 Vector__XXX
 SG_ _segment5Cell1Voltage_V : 7|16@0- (0.001,0) [0|0] "voltage:V" Vector__XXX
 SG_ _segment5Cell2Voltage_V : 23|16@0- (0.001,0) [0|0] "voltage:V" Vector__XXX
 SG_ _segment5Cell3Voltage_V : 39|16@0- (0.001,0) [0|0] "voltage:V" Vector__XXX
 SG_ _segment5Cell4Voltage_V : 55|16@0- (0.001,0) [0|0] "voltage:V" Vector__XXX

BO_ 851 851: 8 Vector__XXX
 SG_ _segment5Cell5Voltage_V : 7|16@0- (0.001,0) [0|0] "voltage:V" Vector__XXX
 SG_ _segment5Cell6Voltage_V : 23|16@0- (0.001,0) [0|0] "voltage:V" Vector__XXX
 SG_ _segment5Cell7Voltage_V : 39|16@0- (0.001,0) [0|0] "voltage:V" Vector__XXX
 SG_ _segment5Cell8Voltage_V : 55|16@0- (0.001,0) [0|0] "voltage:V" Vector__XXX

BO_ 852 852: 8 Vector__XXX
 SG_ _segment5Cell9Voltage_V : 7|16@0- (0.001,0) [0|0] "voltage:V" Vector__XXX
 SG_ _segment5Cell10Voltage_V : 23|16@0- (0.001,0) [0|0] "voltage:V" Vector__XXX
 SG_ _segment5Cell11Voltage_V : 39|16@0- (0.001,0) [0|0] "voltage:V" Vector__XXX
 SG_ _segment5Cell12Voltage_V : 55|16@0- (0.001,0) [0|0] "voltage:V" Vector__XXX

BO_ 853 853: 8 Vector__XXX
 SG_ _segment5Cell13Voltage_V : 7|16@0- (0.001,0) [0|0] "voltage:V" Vector__XXX
 SG_ _segment5Cell14Voltage_V : 23|16@0- (0.001,0) [0|0] "voltage:V" Vector__XXX
 SG_ _segment5Cell15Voltage_V : 39|16@0- (0.001,0) [0|0] "voltage:V" Vector__XXX
 SG_ _segment5Cell16Voltage_V : 55|16@0- (0.001,0) [0|0] "voltage:V" Vector__XXX

BO_ 854 854: 8 Vector__XXX
 SG_ _segment5Cell1Temperature_C : 7|16@0- (0.1,-40) [0|0] "temperature:C" Vector__XXX
 SG_ _segment5Cell2Temperature_C : 23|16@0- (0.1,-40) [0|0] "temperature:C" Vector__XXX
 SG_ _segment5Cell3Temperature_C : 39|16@0- (0.1,-40) [0|0] "temperature:C" Vector__XXX
 SG_ _segment5Cell4Temperature_C : 55|16@0- (0.1,-40) [0|0] "temperature:C" Vector__XXX

BO_ 855 855: 8 Vector__XXX
 SG_ _segment5Cell5Temperature_C : 7|16@0- (0.1,-40) [0|0] "temperature:C" Vector__XXX
 SG_ _segment5Cell6Temperature_C : 23|16@0- (0.1,-40) [0|0] "temperature:C" Vector__XXX
 SG_ _segment5Cell7Temperature_C : 39|16@0- (0.1,-40) [0|0] "temperature:C" Vector__XXX
 SG_ _segment5Cell8Temperature_C : 55|16@0- (0.1,-40) [0|0] "temperature:C" Vector__XXX

BO_ 856 856: 8 Vector__XXX
 SG_ _segment5Cell9Temperature_C : 7|16@0- (0.1,-40) [0|0] "temperature:C" Vector__XXX
 SG_ _segment5Cell10Temperature_C : 23|16@0- (0.1,-40) [0|0] "temperature:C" Vector__XXX
 SG_ _segment5Cell11Temperature_C : 39|16@0- (0.1,-40) [0|0] "temperature:C" Vector__XXX
 SG_ _segment5Cell12Temperature_C : 55|16@0- (0.1,-40) [0|0] "temperature:C" Vector__XXX

BO_ 857 857: 8 Vector__XXX
 SG_ _segment5Cell13Temperature_C : 7|16@0- (0.1,-40) [0|0] "temperature:C" Vector__XXX
 SG_ _segment5Cell14Temperature_C : 23|16@0- (0.1,-40) [0|0] "temperature:C" Vector__XXX
 SG_ _segment5Cell15Temperature_C : 39|16@0- (0.1,-40) [0|0] "temperature:C" Vector__XXX
 SG_ _segment5Cell16Temperature_C : 55|16@0- (0.1,-40) [0|0] "temperature:C" Vector__XXX

BO_ 864 864: 8 Vector__XXX
 SG_ _segment6MaxCellVoltage_V : 7|16@0- (0.001,0) [0|0] "voltage:V" Vector__XXX
 SG_ _segment6MinCellVoltage_V : 23|16@0- (0.001,0) [0|0] "voltage:V" Vector__XXX
 SG_ _segment6AvgCellVoltage_V : 39|16@0- (0.001,0) [0|0] "voltage:V" Vector__XXX
 SG_ _segment6DieTemperature_C : 55|16@0- (0.1,-40) [0|0] "temperature:C" Vector__XXX

BO_ 865 865: 8 Vector__XXX
 SG_ _segment6MaxCellTemperature_C : 7|16@0- (0.1,-40) [0|0] "temperature:C" Vector__XXX
 SG_ _segment6MinCellTemperature_C : 23|16@0- (0.1,-40) [0|0] "temperature:C" Vector__XXX
 SG_ _segment6AvgCellTemperature_C : 39|16@0- (0.1,-40) [0|0] "temperature:C" Vector__XXX
 SG_ _segment6BoardTemperature_C : 55|16@0- (0.1,-40) [0|0] "temperature:C" Vector__XXX

BO_ 866 866: 8 Vector__XXX
 SG_ _segment6Cell1Voltage_V : 7|16@0- (0.001,0) [0|0] "voltage:V" Vector__XXX
 SG_ _segment6Cell2Voltage_V : 23|16@0- (0.001,0) [0|0] "voltage:V" Vector__XXX
 SG_ _segment6Cell3Voltage_V : 39|16@0- (0.001,0) [0|0] "voltage:V" Vector__XXX
 SG_ _segment6Cell4Voltage_V : 55|16@0- (0.001,0) [0|0] "voltage:V" Vector__XXX

BO_ 867 867: 8 Vector__XXX
 SG_ _segment6Cell5Voltage_V : 7|16@0- (0.001,0) [0|0] "voltage:V" Vector__XXX
 SG_ _segment6Cell6Voltage_V : 23|16@0- (0.001,0) [0|0] "voltage:V" Vector__XXX
 SG_ _segment6Cell7Voltage_V : 39|16@0- (0.001,0) [0|0] "voltage:V" Vector__XXX
 SG_ _segment6Cell8Voltage_V : 55|16@0- (0.001,0) [0|0] "voltage:V" Vector__XXX

BO_ 868 868: 8 Vector__XXX
 SG_ _segment6Cell9Voltage_V : 7|16@0- (0.001,0) [0|0] "voltage:V" Vector__XXX
 SG_ _segment6Cell10Voltage_V : 23|16@0- (0.001,0) [0|0] "voltage:V" Vector__XXX
 SG_ _segment6Cell11Voltage_V : 39|16@0- (0.001,0) [0|0] "voltage:V" Vector__XXX
 SG_ _segment6Cell12Voltage_V : 55|16@0- (0.001,0) [0|0] "voltage:V" Vector__XXX

BO_ 869 869: 8 Vector__XXX
 SG_ _segment6Cell13Voltage_V : 7|16@0- (0.001,0) [0|0] "voltage:V" Vector__XXX
 SG_ _segment6Cell14Voltage_V : 23|16@0- (0.001,0) [0|0] "voltage:V" Vector__XXX
 SG_ _segment6Cell15Voltage_V : 39|16@0- (0.001,0) [0|0] "voltage:V" Vector__XXX
 SG_ _segment6Cell16Voltage_V : 55|16@0- (0.001,0) [0|0] "voltage:V" Vector__XXX

BO_ 870 870: 8 Vector__XXX
 SG_ _segment6Cell1Temperature_C : 7|16@0- (0.1,-40) [0|0] "temperature:C" Vector__XXX
 SG_ _segment6Cell2Temperature_C : 23|16@0- (0.1,-40) [0|0] "temperature:C" Vector__XXX
 SG_ _segment6Cell3Temperature_C : 39|16@0- (0.1,-40) [0|0] "temperature:C" Vector__XXX
 SG_ _segment6Cell4Temperature_C : 55|16@0- (0.1,-40) [0|0] "temperature:C" Vector__XXX

BO_ 871 871: 8 Vector__XXX
 SG_ _segment6Cell5Temperature_C : 7|16@0- (0.1,-40) [0|0] "temperature:C" Vector__XXX
 SG_ _segment6Cell6Temperature_C : 23|16@0- (0.1,-40) [0|0] "temperature:C" Vector__XXX
 SG_ _segment6Cell7Temperature_C : 39|16@0- (0.1,-40) [0|0] "temperature:C" Vector__XXX
 SG_ _segment6Cell8Temperature_C : 55|16@0- (0.1,-40) [0|0] "temperature:C" Vector__XXX

BO_ 872 872: 8 Vector__XXX
 SG_ _segment6Cell9Temperature_C : 7|16@0- (0.1,-40) [0|0] "temperature:C" Vector__XXX
 SG_ _segment6Cell10Temperature_C : 23|16@0- (0.1,-40) [0|0] "temperature:C" Vector__XXX
 SG_ _segment6Cell11Temperature_C : 39|16@0- (0.1,-40) [0|0] "temperature:C" Vector__XXX
 SG_ _segment6Cell12Temperature_C : 55|16@0- (0.1,-40) [0|0] "temperature:C" Vector__XXX

BO_ 873 873: 8 Vector__XXX
 SG_ _segment6Cell13Temperature_C : 7|16@0- (0.1,-40) [0|0] "temperature:C" Vector__XXX
 SG_ _segment6Cell14Temperature_C : 23|16@0- (0.1,-40) [0|0] "temperature:C" Vector__XXX
 SG_ _segment6Cell15Temperature_C : 39|16@0- (0.1,-40) [0|0] "temperature:C" Vector__XXX
 SG_ _segment6Cell16Temperature_C : 55|16@0- (0.1,-40) [0|0] "temperature:C" Vector__XXX

BO_ 880 880: 8 Vector__XXX
 SG_ _segment7MaxCellVoltage_V : 7|16@0- (0.001,0) [0|0] "voltage:V" Vector__XXX
 SG_ _segment7MinCellVoltage_V : 23|16@0- (0.001,0) [0|0] "voltage:V" Vector__XXX
 SG_ _segment7AvgCellVoltage_V : 39|16@0- (0.001,0) [0|0] "voltage:V" Vector__XXX
 SG_ _segment7DieTemperature_C : 55|16@0- (0.1,-40) [0|0] "temperature:C" Vector__XXX

BO_ 881 881: 8 Vector__XXX
 SG_ _segment7MaxCellTemperature_C : 7|16@0- (0.1,-40) [0|0] "temperature:C" Vector__XXX
 SG_ _segment7MinCellTemperature_C : 23|16@0- (0.1,-40) [0|0] "temperature:C" Vector__XXX
 SG_ _segment7AvgCellTemperature_C : 39|16@0- (0.1,-40) [0|0] "temperature:C" Vector__XXX
 SG_ _segment7BoardTemperature_C : 55|16@0- (0.1,-40) [0|0] "temperature:C" Vector__XXX

BO_ 882 882: 8 Vector__XXX
 SG_ _segment7Cell1Voltage_V : 7|16@0- (0.001,0) [0|0] "voltage:V" Vector__XXX
 SG_ _segment7Cell2Voltage_V : 23|16@0- (0.001,0) [0|0] "voltage:V" Vector__XXX
 SG_ _segment7Cell3Voltage_V : 39|16@0- (0.001,0) [0|0] "voltage:V" Vector__XXX
 SG_ _segment7Cell4Voltage_V : 55|16@0- (0.001,0) [0|0] "voltage:V" Vector__XXX

BO_ 883 883: 8 Vector__XXX
 SG_ _segment7Cell5Voltage_V : 7|16@0- (0.001,0) [0|0] "voltage:V" Vector__XXX
 SG_ _segment7Cell6Voltage_V : 23|16@0- (0.001,0) [0|0] "voltage:V" Vector__XXX
 SG_ _segment7Cell7Voltage_V : 39|16@0- (0.001,0) [0|0] "voltage:V" Vector__XXX
 SG_ _segment7Cell8Voltage_V : 55|16@0- (0.001,0) [0|0] "voltage:V" Vector__XXX

BO_ 884 884: 8 Vector__XXX
 SG_ _segment7Cell9Voltage_V : 7|16@0- (0.001,0) [0|0] "voltage:V" Vector__XXX
 SG_ _segment7Cell10Voltage_V : 23|16@0- (0.001,0) [0|0] "voltage:V" Vector__XXX
 SG_ _segment7Cell11Voltage_V : 39|16@0- (0.001,0) [0|0] "voltage:V" Vector__XXX
 SG_ _segment7Cell12Voltage_V : 55|16@0- (0.001,0) [0|0] "voltage:V" Vector__XXX

BO_ 885 885: 8 Vector__XXX
 SG_ _segment7Cell13Voltage_V : 7|16@0- (0.001,0) [0|0] "voltage:V" Vector__XXX
 SG_ _segment7Cell14Voltage_V : 23|16@0- (0.001,0) [0|0] "voltage:V" Vector__XXX
 SG_ _segment7Cell15Voltage_V : 39|16@0- (0.001,0) [0|0] "voltage:V" Vector__XXX
 SG_ _segment7Cell16Voltage_V : 55|16@0- (0.001,0) [0|0] "voltage:V" Vector__XXX

BO_ 886 886: 8 Vector__XXX
 SG_ _segment7Cell1Temperature_C : 7|16@0- (0.1,-40) [0|0] "temperature:C" Vector__XXX
 SG_ _segment7Cell2Temperature_C : 23|16@0- (0.1,-40) [0|0] "temperature:C" Vector__XXX
 SG_ _segment7Cell3Temperature_C : 39|16@0- (0.1,-40) [0|0] "temperature:C" Vector__XXX
 SG_ _segment7Cell4Temperature_C : 55|16@0- (0.1,-40) [0|0] "temperature:C" Vector__XXX

BO_ 887 887: 8 Vector__XXX
 SG_ _segment7Cell5Temperature_C : 7|16@0- (0.1,-40) [0|0] "temperature:C" Vector__XXX
 SG_ _segment7Cell6Temperature_C : 23|16@0- (0.1,-40) [0|0] "temperature:C" Vector__XXX
 SG_ _segment7Cell7Temperature_C : 39|16@0- (0.1,-40) [0|0] "temperature:C" Vector__XXX
 SG_ _segment7Cell8Temperature_C : 55|16@0- (0.1,-40) [0|0] "temperature:C" Vector__XXX

BO_ 888 888: 8 Vector__XXX
 SG_ _segment7Cell9Temperature_C : 7|16@0- (0.1,-40) [0|0] "temperature:C" Vector__XXX
 SG_ _segment7Cell10Temperature_C : 23|16@0- (0.1,-40) [0|0] "temperature:C" Vector__XXX
 SG_ _segment7Cell11Temperature_C : 39|16@0- (0.1,-40) [0|0] "temperature:C" Vector__XXX
 SG_ _segment7Cell12Temperature_C : 55|16@0- (0.1,-40) [0|0] "temperature:C" Vector__XXX

BO_ 889 889: 8 Vector__XXX
 SG_ _segment7Cell13Temperature_C : 7|16@0- (0.1,-40) [0|0] "temperature:C" Vector__XXX
 SG_ _segment7Cell14Temperature_C : 23|16@0- (0.1,-40) [0|0] "temperature:C" Vector__XXX
 SG_ _segment7Cell15Temperature_C : 39|16@0- (0.1,-40) [0|0] "temperature:C" Vector__XXX
 SG_ _segment7Cell16Temperature_C : 55|16@0- (0.1,-40) [0|0] "temperature:C" Vector__XXX

BO_ 896 896: 8 Vector__XXX
 SG_ _segment8MaxCellVoltage_V : 7|16@0- (0.001,0) [0|0] "voltage:V" Vector__XXX
 SG_ _segment8MinCellVoltage_V : 23|16@0- (0.001,0) [0|0] "voltage:V" Vector__XXX
 SG_ _segment8AvgCellVoltage_V : 39|16@0- (0.001,0) [0|0] "voltage:V" Vector__XXX
 SG_ _segment8DieTemperature_C : 55|16@0- (0.1,-40) [0|0] "temperature:C" Vector__XXX

BO_ 897 897: 8 Vector__XXX
 SG_ _segment8MaxCellTemperature_C : 7|16@0- (0.1,-40) [0|0] "temperature:C" Vector__XXX
 SG_ _segment8MinCellTemperature_C : 23|16@0- (0.1,-40) [0|0] "temperature:C" Vector__XXX
 SG_ _segment8AvgCellTemperature_C : 39|16@0- (0.1,-40) [0|0] "temperature:C" Vector__XXX
 SG_ _segment8BoardTemperature_C : 55|16@0- (0.1,-40) [0|0] "temperature:C" Vector__XXX

BO_ 898 898: 8 Vector__XXX
 SG_ _segment8Cell1Voltage_V : 7|16@0- (0.001,0) [0|0] "voltage:V" Vector__XXX
 SG_ _segment8Cell2Voltage_V : 23|16@0- (0.001,0) [0|0] "voltage:V" Vector__XXX
 SG_ _segment8Cell3Voltage_V : 39|16@0- (0.001,0) [0|0] "voltage:V" Vector__XXX
 SG_ _segment8Cell4Voltage_V : 55|16@0- (0.001,0) [0|0] "voltage:V" Vector__XXX

BO_ 899 899: 8 Vector__XXX
 SG_ _segment8Cell5Voltage_V : 7|16@0- (0.001,0) [0|0] "voltage:V" Vector__XXX
 SG_ _segment8Cell6Voltage_V : 23|16@0- (0.001,0) [0|0] "voltage:V" Vector__XXX
 SG_ _segment8Cell7Voltage_V : 39|16@0- (0.001,0) [0|0] "voltage:V" Vector__XXX
 SG_ _segment8Cell8Voltage_V : 55|16@0- (0.001,0) [0|0] "voltage:V" Vector__XXX

BO_ 900 900: 8 Vector__XXX
 SG_ _segment8Cell9Voltage_V : 7|16@0- (0.001,0) [0|0] "voltage:V" Vector__XXX
 SG_ _segment8Cell10Voltage_V : 23|16@0- (0.001,0) [0|0] "voltage:V" Vector__XXX
 SG_ _segment8Cell11Voltage_V : 39|16@0- (0.001,0) [0|0] "voltage:V" Vector__XXX
 SG_ _segment8Cell12Voltage_V : 55|16@0- (0.001,0) [0|0] "voltage:V" Vector__XXX

BO_ 901 901: 8 Vector__XXX
 SG_ _segment8Cell13Voltage_V : 7|16@0- (0.001,0) [0|0] "voltage:V" Vector__XXX
 SG_ _segment8Cell14Voltage_V : 23|16@0- (0.001,0) [0|0] "voltage:V" Vector__XXX
 SG_ _segment8Cell15Voltage_V : 39|16@0- (0.001,0) [0|0] "voltage:V" Vector__XXX
 SG_ _segment8Cell16Voltage_V : 55|16@0- (0.001,0) [0|0] "voltage:V" Vector__XXX

BO_ 902 902: 8 Vector__XXX
 SG_ _segment8Cell1Temperature_C : 7|16@0- (0.1,-40) [0|0] "temperature:C" Vector__XXX
 SG_ _segment8Cell2Temperature_C : 23|16@0- (0.1,-40) [0|0] "temperature:C" Vector__XXX
 SG_ _segment8Cell3Temperature_C : 39|16@0- (0.1,-40) [0|0] "temperature:C" Vector__XXX
 SG_ _segment8Cell4Temperature_C : 55|16@0- (0.1,-40) [0|0] "temperature:C" Vector__XXX

BO_ 903 903: 8 Vector__XXX
 SG_ _segment8Cell5Temperature_C : 7|16@0- (0.1,-40) [0|0] "temperature:C" Vector__XXX
 SG_ _segment8Cell6Temperature_C : 23|16@0- (0.1,-40) [0|0] "temperature:C" Vector__XXX
 SG_ _segment8Cell7Temperature_C : 39|16@0- (0.1,-40) [0|0] "temperature:C" Vector__XXX
 SG_ _segment8Cell8Temperature_C : 55|16@0- (0.1,-40) [0|0] "temperature:C" Vector__XXX

BO_ 904 904: 8 Vector__XXX
 SG_ _segment8Cell9Temperature_C : 7|16@0- (0.1,-40) [0|0] "temperature:C" Vector__XXX
 SG_ _segment8Cell10Temperature_C : 23|16@0- (0.1,-40) [0|0] "temperature:C" Vector__XXX
 SG_ _segment8Cell11Temperature_C : 39|16@0- (0.1,-40) [0|0] "temperature:C" Vector__XXX
 SG_ _segment8Cell12Temperature_C : 55|16@0- (0.1,-40) [0|0] "temperature:C" Vector__XXX

BO_ 905 905: 8 Vector__XXX
 SG_ _segment8Cell13Temperature_C : 7|16@0- (0.1,-40) [0|0] "temperature:C" Vector__XXX
 SG_ _segment8Cell14Temperature_C : 23|16@0- (0.1,-40) [0|0] "temperature:C" Vector__XXX
 SG_ _segment8Cell15Temperature_C : 39|16@0- (0.1,-40) [0|0] "temperature:C" Vector__XXX
 SG_ _segment8Cell16Temperature_C : 55|16@0- (0.1,-40) [0|0] "temperature:C" Vector__XXX

BO_ 912 912: 8 Vector__XXX
 SG_ _chargerVoltageSetPoint_V : 7|16@0- (0.1,0) [0|0] "voltage:V" Vector__XXX
 SG_ _chargerCurrentSetPoint_A : 23|16@0- (0.1,0) [0|0] "current:A" Vector__XXX
 SG_ _chargerStatusByte : 39|8@0+ (1,0) [0|0] "unitless:" Vector__XXX

BO_ 0 0: 8 Vector__XXX
 SG_ _vbatChan0Current_A : 7|16@0- (0.00741391941,0) [0|0] "voltage:V" Vector__XXX
 SG_ _vbatChan1Current_A : 23|16@0- (0.00741391941,0) [0|0] "voltage:V" Vector__XXX
 SG_ _vbatChan2Current_A : 39|16@0- (0.00741391941,0) [0|0] "voltage:V" Vector__XXX
 SG_ _vbatChan3Current_A : 55|16@0- (0.00741391941,0) [0|0] "voltage:V" Vector__XXX

BO_ 1 1: 8 Vector__XXX
 SG_ _vbatChan4Current_A : 7|16@0- (0.00741391941,0) [0|0] "voltage:V" Vector__XXX
 SG_ _vbatChan5Current_A : 23|16@0- (0.00741391941,0) [0|0] "voltage:V" Vector__XXX
 SG_ _vbatChan6Current_A : 39|16@0- (0.00741391941,0) [0|0] "voltage:V" Vector__XXX
 SG_ _fiveVChan0Current_A : 55|16@0- (0.00196141636,0) [0|0] "voltage:V" Vector__XXX

BO_ 2 2: 8 Vector__XXX
 SG_ _fiveVChan1Current_A : 7|16@0- (0.00196141636,0) [0|0] "voltage:V" Vector__XXX
 SG_ _fiveVChan2Current_A : 23|16@0- (0.00196141636,0) [0|0] "voltage:V" Vector__XXX
 SG_ _fiveVChan3Current_A : 39|16@0- (0.00196141636,0) [0|0] "voltage:V" Vector__XXX
 SG_ _can0Utilization_percent : 55|16@0- (0.1,0) [0|0] "fraction:%" Vector__XXX

BO_ 3 3: 8 Vector__XXX
 SG_ _can1Utilization_percent : 7|16@0- (0.1,0) [0|0] "fraction:%" Vector__XXX
 SG_ _can2Utilization_percent : 23|16@0- (0.1,0) [0|0] "fraction:%" Vector__XXX
 SG_ _plmVbatVoltage_V : 39|16@0- (0.00506178266,0) [0|0] "voltage:V" Vector__XXX
 SG_ _plm5VVoltage_V : 55|16@0- (0.00195457875,0) [0|0] "voltage:V" Vector__XXX

BO_ 4 4: 8 Vector__XXX
 SG_ _packetsLogged_ul : 7|32@0+ (1,0) [0|0] "unitless:" Vector__XXX
 SG_ _packetsDropped_ul : 39|32@0+ (1,0) [0|0] "unitless:" Vector__XXX

BO_ 5 5: 8 Vector__XXX
 SG_ _storageBufferFill_percent : 7|16@0- (0.1,0) [0|0] "fraction:%" Vector__XXX
 SG_ _telemetryBufferFill_percent : 23|16@0- (0.1,0) [0|0] "fraction:%" Vector__XXX

BO_ 6 6: 8 Vector__XXX
 SG_ _PLM_Temp_degrees : 7|16@0- (0.002518,-40) [0|0] "temperature:C" Vector__XXX
 SG_ _PLM_Humidity_percent : 23|16@0- (0.024414,0) [0|0] "fraction:%" Vector__XXX
 SG_ _PLM_Micro_Temp : 39|16@0- (0.024414,0) [0|0] "fraction:%" Vector__XXX

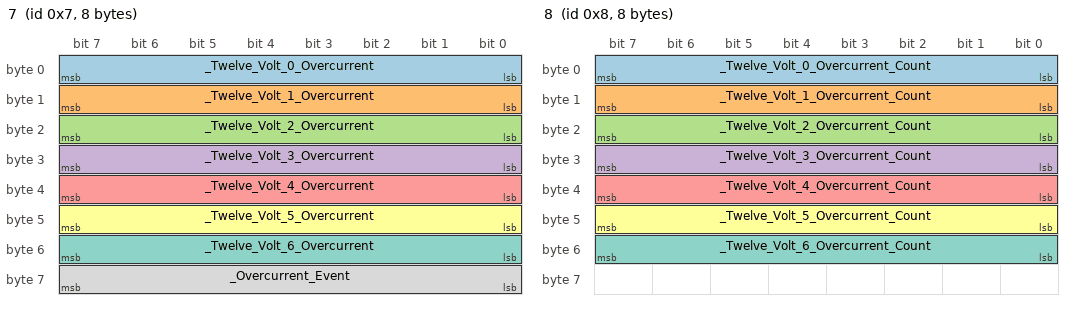
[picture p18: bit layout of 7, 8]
BO_ 7 7: 8 Vector__XXX
 SG_ _Twelve_Volt_0_Overcurrent : 7|8@0+ (1,0) [0|0] "unitless:" Vector__XXX
 SG_ _Twelve_Volt_1_Overcurrent : 15|8@0+ (1,0) [0|0] "unitless:" Vector__XXX
 SG_ _Twelve_Volt_2_Overcurrent : 23|8@0+ (1,0) [0|0] "unitless:" Vector__XXX
 SG_ _Twelve_Volt_3_Overcurrent : 31|8@0+ (1,0) [0|0] "unitless:" Vector__XXX
 SG_ _Twelve_Volt_4_Overcurrent : 39|8@0+ (1,0) [0|0] "unitless:" Vector__XXX
 SG_ _Twelve_Volt_5_Overcurrent : 47|8@0+ (1,0) [0|0] "unitless:" Vector__XXX
 SG_ _Twelve_Volt_6_Overcurrent : 55|8@0+ (1,0) [0|0] "unitless:" Vector__XXX
 SG_ _Overcurrent_Event : 63|8@0+ (1,0) [0|0] "unitless:" Vector__XXX

BO_ 8 8: 8 Vector__XXX
 SG_ _Twelve_Volt_0_Overcurrent_Count : 7|8@0+ (1,0) [0|0] "unitless:" Vector__XXX
 SG_ _Twelve_Volt_1_Overcurrent_Count : 15|8@0+ (1,0) [0|0] "unitless:" Vector__XXX
 SG_ _Twelve_Volt_2_Overcurrent_Count : 23|8@0+ (1,0) [0|0] "unitless:" Vector__XXX
 SG_ _Twelve_Volt_3_Overcurrent_Count : 31|8@0+ (1,0) [0|0] "unitless:" Vector__XXX
 SG_ _Twelve_Volt_4_Overcurrent_Count : 39|8@0+ (1,0) [0|0] "unitless:" Vector__XXX
 SG_ _Twelve_Volt_5_Overcurrent_Count : 47|8@0+ (1,0) [0|0] "unitless:" Vector__XXX
 SG_ _Twelve_Volt_6_Overcurrent_Count : 55|8@0+ (1,0) [0|0] "unitless:" Vector__XXX

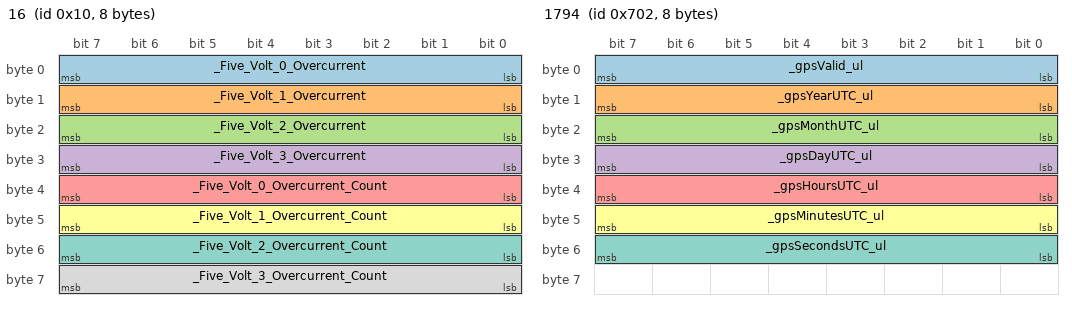
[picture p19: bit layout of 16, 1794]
BO_ 16 16: 8 Vector__XXX
 SG_ _Five_Volt_0_Overcurrent : 7|8@0+ (1,0) [0|0] "unitless:" Vector__XXX
 SG_ _Five_Volt_1_Overcurrent : 15|8@0+ (1,0) [0|0] "unitless:" Vector__XXX
 SG_ _Five_Volt_2_Overcurrent : 23|8@0+ (1,0) [0|0] "unitless:" Vector__XXX
 SG_ _Five_Volt_3_Overcurrent : 31|8@0+ (1,0) [0|0] "unitless:" Vector__XXX
 SG_ _Five_Volt_0_Overcurrent_Count : 39|8@0+ (1,0) [0|0] "unitless:" Vector__XXX
 SG_ _Five_Volt_1_Overcurrent_Count : 47|8@0+ (1,0) [0|0] "unitless:" Vector__XXX
 SG_ _Five_Volt_2_Overcurrent_Count : 55|8@0+ (1,0) [0|0] "unitless:" Vector__XXX
 SG_ _Five_Volt_3_Overcurrent_Count : 63|8@0+ (1,0) [0|0] "unitless:" Vector__XXX

BO_ 1792 1792: 8 Vector__XXX
 SG_ _gpsLatitude_deg : 7|32@0- (2.1457672119140625e-05,0) [0|0] "angle:deg" Vector__XXX
 SG_ _gpsLongitude_deg : 39|32@0- (2.1457672119140625e-05,0) [0|0] "angle:deg" Vector__XXX

BO_ 1793 1793: 8 Vector__XXX
 SG_ _gpsSpeed_mph : 7|16@0+ (0.01,0) [0|0] "speed:mph" Vector__XXX
 SG_ _gpsAltitude_ft : 23|16@0- (1,0) [0|0] "distance:ft" Vector__XXX
 SG_ _gpsCourse_deg : 39|16@0+ (0.01,0) [0|0] "angle:deg" Vector__XXX
 SG_ _gpsSatelliteCount_ul : 55|8@0+ (1,0) [0|0] "unitless:" Vector__XXX

BO_ 1794 1794: 8 Vector__XXX
 SG_ _gpsValid_ul : 7|8@0+ (1,0) [0|0] "unitless:" Vector__XXX
 SG_ _gpsYearUTC_ul : 15|8@0+ (1,0) [0|0] "unitless:" Vector__XXX
 SG_ _gpsMonthUTC_ul : 23|8@0+ (1,0) [0|0] "unitless:" Vector__XXX
 SG_ _gpsDayUTC_ul : 31|8@0+ (1,0) [0|0] "unitless:" Vector__XXX
 SG_ _gpsHoursUTC_ul : 39|8@0+ (1,0) [0|0] "unitless:" Vector__XXX
 SG_ _gpsMinutesUTC_ul : 47|8@0+ (1,0) [0|0] "unitless:" Vector__XXX
 SG_ _gpsSecondsUTC_ul : 55|8@0+ (1,0) [0|0] "unitless:" Vector__XXX

BO_ 112 112: 8 Vector__XXX
 SG_ _yawRate_degPerSec : 0|16@1- (0.005,-163.84) [0|0] "angular_speed:deg/s" Vector__XXX
 SG_ _lateralAccel_G : 32|16@1- (0.0001274,-4.1746432) [0|0] "acceleration:G" Vector__XXX

BO_ 128 128: 8 Vector__XXX
 SG_ _rollRate_degPerSec : 0|16@1- (0.005,-163.84) [0|0] "angular_speed:deg/s" Vector__XXX
 SG_ _longitudinalAccel_G : 32|16@1- (0.0001274,-4.1746432) [0|0] "acceleration:G" Vector__XXX

BO_ 1398 1398: 8 Vector__XXX
 SG_ _verticalAccel_G : 32|16@1- (0.0001274,-4.1746432) [0|0] "acceleration:G" Vector__XXX

BO_ 229 229: 8 Vector__XXX
 SG_ _lapBeaconRaw_ul : 7|24@0- (1,0) [0|0] "unitless:" Vector__XXX

BO_ 230 230: 8 Vector__XXX
 SG_ _lapBeacon_ul : 7|8@0- (1,0) [0|0] "unitless:" Vector__XXX

BO_ 1200 1200: 8 Vector__XXX
 SG_ _rearRightTireTempCh1 : 7|16@0- (0.1,-100.0) [0|0] "temperature:C" Vector__XXX

BO_ 1201 1201: 8 Vector__XXX
 SG_ _rearRightTireTempCh5 : 7|16@0- (0.1,-100.0) [0|0] "temperature:C" Vector__XXX
 SG_ _rearRightTireTempCh7 : 39|16@0- (0.1,-100.0) [0|0] "temperature:C" Vector__XXX
 SG_ _rearRightTireTempCh8 : 55|16@0- (0.1,-100.0) [0|0] "temperature:C" Vector__XXX

BO_ 1202 1202: 8 Vector__XXX
 SG_ _rearRightTireTempCh9 : 7|16@0- (0.1,-100.0) [0|0] "temperature:C" Vector__XXX
 SG_ _rearRightTireTempCh10 : 23|16@0- (0.1,-100.0) [0|0] "temperature:C" Vector__XXX
 SG_ _rearRightTireTempCh12 : 55|16@0- (0.1,-100.0) [0|0] "temperature:C" Vector__XXX

BO_ 1203 1203: 8 Vector__XXX
 SG_ _rearRightTireTempCh16 : 55|16@0- (0.1,-100.0) [0|0] "temperature:C" Vector__XXX

BO_ 1208 1208: 8 Vector__XXX
 SG_ _frontRightTireTempCh1 : 7|16@0- (0.1,-100.0) [0|0] "temperature:C" Vector__XXX

BO_ 1209 1209: 8 Vector__XXX
 SG_ _frontRightTireTempCh5 : 7|16@0- (0.1,-100.0) [0|0] "temperature:C" Vector__XXX
 SG_ _frontRightTireTempCh7 : 39|16@0- (0.1,-100.0) [0|0] "temperature:C" Vector__XXX
 SG_ _frontRightTireTempCh8 : 55|16@0- (0.1,-100.0) [0|0] "temperature:C" Vector__XXX

BO_ 1210 1210: 8 Vector__XXX
 SG_ _frontRightTireTempCh9 : 7|16@0- (0.1,-100.0) [0|0] "temperature:C" Vector__XXX
 SG_ _frontRightTireTempCh10 : 23|16@0- (0.1,-100.0) [0|0] "temperature:C" Vector__XXX
 SG_ _frontRightTireTempCh12 : 55|16@0- (0.1,-100.0) [0|0] "temperature:C" Vector__XXX

BO_ 1211 1211: 8 Vector__XXX
 SG_ _frontRightTireTempCh16 : 55|16@0- (0.1,-100.0) [0|0] "temperature:C" Vector__XXX

BO_ 1212 1212: 8 Vector__XXX
 SG_ _frontLeftTireTempCh1 : 7|16@0- (0.1,-100.0) [0|0] "temperature:C" Vector__XXX

BO_ 1213 1213: 8 Vector__XXX
 SG_ _frontLeftTireTempCh5 : 7|16@0- (0.1,-100.0) [0|0] "temperature:C" Vector__XXX
 SG_ _frontLeftTireTempCh7 : 39|16@0- (0.1,-100.0) [0|0] "temperature:C" Vector__XXX
 SG_ _frontLeftTireTempCh8 : 55|16@0- (0.1,-100.0) [0|0] "temperature:C" Vector__XXX

BO_ 1214 1214: 8 Vector__XXX
 SG_ _frontLeftTireTempCh9 : 7|16@0- (0.1,-100.0) [0|0] "temperature:C" Vector__XXX
 SG_ _frontLeftTireTempCh10 : 23|16@0- (0.1,-100.0) [0|0] "temperature:C" Vector__XXX
 SG_ _frontLeftTireTempCh12 : 55|16@0- (0.1,-100.0) [0|0] "temperature:C" Vector__XXX

BO_ 1215 1215: 8 Vector__XXX
 SG_ _frontLeftTireTempCh16 : 55|16@0- (0.1,-100.0) [0|0] "temperature:C" Vector__XXX

BO_ 1204 1204: 8 Vector__XXX
 SG_ _rearLeftTireTempCh1 : 7|16@0- (0.1,-100.0) [0|0] "temperature:C" Vector__XXX

BO_ 1205 1205: 8 Vector__XXX
 SG_ _rearLeftTireTempCh5 : 7|16@0- (0.1,-100.0) [0|0] "temperature:C" Vector__XXX
 SG_ _rearLeftTireTempCh7 : 39|16@0- (0.1,-100.0) [0|0] "temperature:C" Vector__XXX
 SG_ _rearLeftTireTempCh8 : 55|16@0- (0.1,-100.0) [0|0] "temperature:C" Vector__XXX

BO_ 1206 1206: 8 Vector__XXX
 SG_ _rearLeftTireTempCh9 : 7|16@0- (0.1,-100.0) [0|0] "temperature:C" Vector__XXX
 SG_ _rearLeftTireTempCh10 : 23|16@0- (0.1,-100.0) [0|0] "temperature:C" Vector__XXX
 SG_ _rearLeftTireTempCh12 : 55|16@0- (0.1,-100.0) [0|0] "temperature:C" Vector__XXX

BO_ 1207 1207: 8 Vector__XXX
 SG_ _rearLeftTireTempCh16 : 55|16@0- (0.1,-100.0) [0|0] "temperature:C" Vector__XXX

BO_ 1872 1872: 8 Vector__XXX
 SG_ _tm_CAN1Util_percent : 7|16@0- (0.1,0) [0|0] "fraction:%" Vector__XXX
 SG_ _tm_CAN2Util_percent : 23|16@0- (0.1,0) [0|0] "fraction:%" Vector__XXX
 SG_ _tm_SDBufferFill_percent : 39|16@0- (0.1,0) [0|0] "fraction:%" Vector__XXX
 SG_ _tm_RadioBufferFill_percent : 55|16@0- (0.1,0) [0|0] "fraction:%" Vector__XXX

BO_ 1873 1873: 8 Vector__XXX
 SG_ _tm_SDBytesTransferred_bytes : 7|32@0+ (1,0) [0|0] "unitless:" Vector__XXX
 SG_ _tm_RadioBytesTransferred_bytes : 39|32@0+ (1,0) [0|0] "unitless:" Vector__XXX

BO_ 1874 1874: 8 Vector__XXX
 SG_ _tm_SDPacketsDropped_ul : 7|32@0+ (1,0) [0|0] "unitless:" Vector__XXX
 SG_ _tm_RadioPacketsDropped_ul : 39|32@0+ (1,0) [0|0] "unitless:" Vector__XXX

BO_ 1875 1875: 8 Vector__XXX
 SG_ _tm_CoinBattery_V : 7|16@0- (0.01,0) [0|0] "voltage:V" Vector__XXX

BO_ 1876 1876: 8 Vector__XXX
 SG_ _sdcStatus17 : 7|8@0+ (1,0) [0|0] "unitless:" Vector__XXX
 SG_ _sdcStatus18 : 15|8@0+ (1,0) [0|0] "unitless:" Vector__XXX
 SG_ _sdcStatus19 : 23|8@0+ (1,0) [0|0] "unitless:" Vector__XXX

BO_ 1877 1877: 8 Vector__XXX
 SG_ _chargingPowerLimit : 7|16@0- (1,0) [0|0] "unitless:" Vector__XXX
 SG_ _forceEnableBalancing_state : 23|8@0+ (1,0) [0|0] "unitless:" Vector__XXX

BO_ 1878 1878: 8 Vector__XXX
 SG_ _sdcStatus5 : 7|16@0+ (1,0) [0|0] "unitless:" Vector__XXX
 SG_ _sdcStatus6 : 23|16@0+ (1,0) [0|0] "unitless:" Vector__XXX
 SG_ _sdcStatus7 : 39|16@0+ (1,0) [0|0] "unitless:" Vector__XXX
